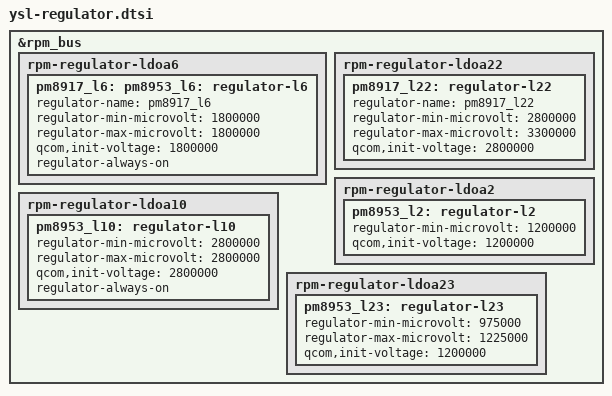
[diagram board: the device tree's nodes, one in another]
/*
 * Copyright (c) 2015-2016, The Linux Foundation. All rights reserved.
 * Copyright (C) 2019 XiaoMi, Inc.
 *
 * This program is free software; you can redistribute it and/or modify
 * it under the terms of the GNU General Public License version 2 and
 * only version 2 as published by the Free Software Foundation.
 *
 * This program is distributed in the hope that it will be useful,
 * but WITHOUT ANY WARRANTY; without even the implied warranty of
 * MERCHANTABILITY or FITNESS FOR A PARTICULAR PURPOSE.  See the
 * GNU General Public License for more details.
 */

/* msm8917-regulator */
&rpm_bus {
       rpm-regulator-ldoa6 {
		status = "okay";
		pm8917_l6: regulator-l6 {
			regulator-name = "pm8917_l6";
			regulator-min-microvolt = <1800000>;
			regulator-max-microvolt = <1800000>;
			qcom,init-voltage = <1800000>;
			status = "okay";
			regulator-always-on;
		};
	};
	
	rpm-regulator-ldoa22 {
		status = "okay";
		pm8917_l22: regulator-l22 {
			regulator-name = "pm8917_l22";
			regulator-min-microvolt = <2800000>;
			regulator-max-microvolt = <3300000>;
			qcom,init-voltage = <2800000>;
			status = "okay";
		};
	};
};

/* msm8953-regulator */
&rpm_bus {
	rpm-regulator-ldoa2 {
		pm8953_l2: regulator-l2 {
			regulator-min-microvolt = <1200000>;
			qcom,init-voltage = <1200000>;
		};
	};
	rpm-regulator-ldoa6 {
		status = "okay";
		pm8953_l6: regulator-l6 {
			regulator-min-microvolt = <1800000>;
			regulator-max-microvolt = <1800000>;
			qcom,init-voltage = <1800000>;
			status = "okay";
			regulator-always-on;
		};
	};
	rpm-regulator-ldoa10 {
		pm8953_l10: regulator-l10 {
			regulator-min-microvolt = <2800000>;
			regulator-max-microvolt = <2800000>;
			qcom,init-voltage = <2800000>;
			regulator-always-on;
		};
	};
	rpm-regulator-ldoa23 {
		pm8953_l23: regulator-l23 {
			regulator-min-microvolt = <975000>;
			regulator-max-microvolt = <1225000>;
			qcom,init-voltage = <1200000>;
		};
	};
};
